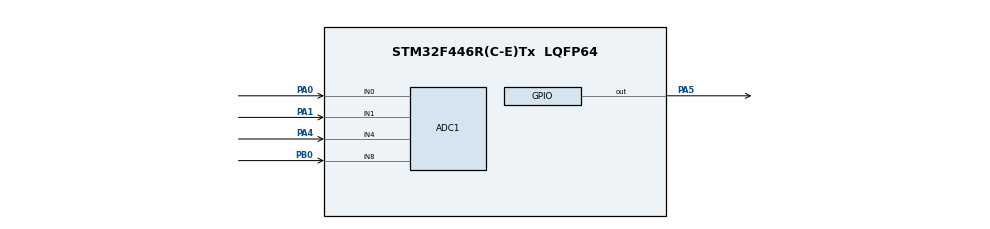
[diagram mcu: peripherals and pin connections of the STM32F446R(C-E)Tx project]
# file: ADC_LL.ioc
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ADC1.Channel-0\#ChannelRegularConversion=ADC_CHANNEL_0
ADC1.Channel-1\#ChannelRegularConversion=ADC_CHANNEL_1
ADC1.Channel-2\#ChannelRegularConversion=ADC_CHANNEL_4
ADC1.Channel-3\#ChannelRegularConversion=ADC_CHANNEL_8
ADC1.ClockPrescaler=ADC_CLOCK_SYNC_PCLK_DIV8
ADC1.ContinuousConvMode=DISABLE
ADC1.DMAContinuousRequests=ENABLE
ADC1.EOCSelection=ADC_EOC_SEQ_CONV
ADC1.ExternalTrigConv=ADC_EXTERNALTRIGCONV_T2_TRGO
ADC1.NbrOfConversion=4
ADC1.NbrOfConversionFlag=1
ADC1.Rank-0\#ChannelRegularConversion=1
ADC1.Rank-1\#ChannelRegularConversion=2
ADC1.Rank-2\#ChannelRegularConversion=3
ADC1.Rank-3\#ChannelRegularConversion=4
ADC1.SamplingTime-0\#ChannelRegularConversion=ADC_SAMPLETIME_3CYCLES
ADC1.SamplingTime-1\#ChannelRegularConversion=ADC_SAMPLETIME_3CYCLES
ADC1.SamplingTime-2\#ChannelRegularConversion=ADC_SAMPLETIME_3CYCLES
ADC1.SamplingTime-3\#ChannelRegularConversion=ADC_SAMPLETIME_3CYCLES
ADC1.ScanConvMode=ENABLE
ADC1.master=1
Dma.ADC1.0.Direction=DMA_PERIPH_TO_MEMORY
Dma.ADC1.0.FIFOMode=DMA_FIFOMODE_DISABLE
Dma.ADC1.0.Instance=DMA2_Stream0
Dma.ADC1.0.MemDataAlignment=DMA_MDATAALIGN_HALFWORD
Dma.ADC1.0.MemInc=DMA_MINC_ENABLE
Dma.ADC1.0.Mode=DMA_CIRCULAR
Dma.ADC1.0.PeriphDataAlignment=DMA_PDATAALIGN_HALFWORD
Dma.ADC1.0.PeriphInc=DMA_PINC_DISABLE
Dma.ADC1.0.Priority=DMA_PRIORITY_LOW
Dma.Request0=ADC1
Mcu.Family=STM32F4
Mcu.Name=STM32F446R(C-E)Tx
Mcu.Package=LQFP64
NVIC.ADC_IRQn=true\:0\:0\:false\:false\:false\:true\:true\:true
NVIC.DMA2_Stream0_IRQn=true\:0\:0\:false\:false\:false\:true\:true\:true
NVIC.PriorityGroup=NVIC_PRIORITYGROUP_4
PA0-WKUP.Signal=ADCx_IN0
PA1.Signal=ADCx_IN1
PA4.Signal=ADCx_IN4
PA5.Signal=GPIO_Output
PB0.Signal=ADCx_IN8
ProjectManager.HeapSize=0x200
ProjectManager.StackSize=0x400
ProjectManager.TargetToolchain=STM32CubeIDE
RCC.CortexFreq_Value=16000000
RCC.USBFreq_Value=96000000
RCC.VCOOutputFreq_Value=192000000
SH.ADCx_IN0.0=ADC1_IN0,IN0
SH.ADCx_IN1.0=ADC1_IN1,IN1
SH.ADCx_IN4.0=ADC1_IN4,IN4
SH.ADCx_IN8.0=ADC1_IN8,IN8
TIM2.Period=100-1
TIM2.Prescaler=16000-1
TIM2.TIM_MasterOutputTrigger=TIM_TRGO_UPDATE
VP_TIM2_VS_ClockSourceINT.Mode=Internal
board=custom

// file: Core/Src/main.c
/* USER CODE BEGIN Header */
/**
  ******************************************************************************
  * @file           : main.c
  * @brief          : Main program body
  ******************************************************************************
  * @attention
  *
  * Copyright (c) 2026 STMicroelectronics.
  * All rights reserved.
  *
  * This software is licensed under terms that can be found in the LICENSE file
  * in the root directory of this software component.
  * If no LICENSE file comes with this software, it is provided AS-IS.
  *
  ******************************************************************************
  */
/* USER CODE END Header */
#include "main.h"
#include "adc.h"
#include "dma.h"
#include "tim.h"
#include "gpio.h"

/* USER CODE BEGIN PV */
uint16_t adc_value[4];
/* USER CODE END PV */

void SystemClock_Config(void);

/* USER CODE BEGIN 0 */
void ADC_DMA_TransferCompleteCallback(void)
{
	LL_GPIO_TogglePin(GPIOA, LL_GPIO_PIN_5);
}
/* USER CODE END 0 */

int main(void)
{

  /* MCU Configuration--------------------------------------------------------*/

  /* Reset of all peripherals, Initializes the Flash interface and the Systick. */
  HAL_Init();

  /* Configure the system clock */
  SystemClock_Config();

  /* Initialize all configured peripherals */
  MX_GPIO_Init();
  MX_DMA_Init();
  MX_ADC1_Init();
  MX_TIM2_Init();
  /* USER CODE BEGIN 2 */
  //ADC_Start_DMA_SingleCHannel(&adc_value);
  ADC_Start_DMA_MultiChannnel_TIM2Trig(adc_value,4);
  /* USER CODE END 2 */

  /* Infinite loop */
  while (1)
  {

  }
}

void SystemClock_Config(void)
{
  RCC_OscInitTypeDef RCC_OscInitStruct = {0};
  RCC_ClkInitTypeDef RCC_ClkInitStruct = {0};

  /** Configure the main internal regulator output voltage
  */
  __HAL_RCC_PWR_CLK_ENABLE();
  __HAL_PWR_VOLTAGESCALING_CONFIG(PWR_REGULATOR_VOLTAGE_SCALE3);

  /** Initializes the RCC Oscillators according to the specified parameters
  * in the RCC_OscInitTypeDef structure.
  */
  RCC_OscInitStruct.OscillatorType = RCC_OSCILLATORTYPE_HSI;
  RCC_OscInitStruct.HSIState = RCC_HSI_ON;
  RCC_OscInitStruct.HSICalibrationValue = RCC_HSICALIBRATION_DEFAULT;
  RCC_OscInitStruct.PLL.PLLState = RCC_PLL_NONE;
  if (HAL_RCC_OscConfig(&RCC_OscInitStruct) != HAL_OK)
  {
    Error_Handler();
  }

  /** Initializes the CPU, AHB and APB buses clocks
  */
  RCC_ClkInitStruct.ClockType = RCC_CLOCKTYPE_HCLK|RCC_CLOCKTYPE_SYSCLK
                              |RCC_CLOCKTYPE_PCLK1|RCC_CLOCKTYPE_PCLK2;
  RCC_ClkInitStruct.SYSCLKSource = RCC_SYSCLKSOURCE_HSI;
  RCC_ClkInitStruct.AHBCLKDivider = RCC_SYSCLK_DIV1;
  RCC_ClkInitStruct.APB1CLKDivider = RCC_HCLK_DIV1;
  RCC_ClkInitStruct.APB2CLKDivider = RCC_HCLK_DIV1;

  if (HAL_RCC_ClockConfig(&RCC_ClkInitStruct, FLASH_LATENCY_0) != HAL_OK)
  {
    Error_Handler();
  }
}

void Error_Handler(void)
{
  __disable_irq();
  while (1)
  {
  }
}
